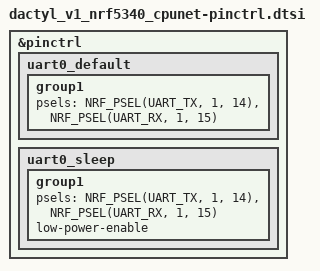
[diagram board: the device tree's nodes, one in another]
&pinctrl {
	uart0_default: uart0_default {
		group1 {
			psels = <NRF_PSEL(UART_TX, 1, 14)>,
				<NRF_PSEL(UART_RX, 1, 15)>;
		};
	};

	uart0_sleep: uart0_sleep {
		group1 {
			psels = <NRF_PSEL(UART_TX, 1, 14)>,
				<NRF_PSEL(UART_RX, 1, 15)>;
			low-power-enable;
		};
	};

};
